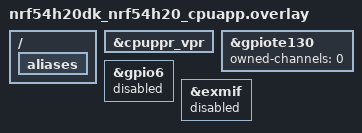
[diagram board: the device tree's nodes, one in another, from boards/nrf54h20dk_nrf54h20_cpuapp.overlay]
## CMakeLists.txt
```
#
# Copyright (c) 2024 Nordic Semiconductor ASA
#
# SPDX-License-Identifier: LicenseRef-Nordic-5-Clause
#

cmake_minimum_required(VERSION 3.20.0)

find_package(Zephyr REQUIRED HINTS $ENV{ZEPHYR_BASE})

if(NOT SYSBUILD)
	message(FATAL_ERROR
		" This is a multi-image application that should be built using sysbuild.\n"
		" Add --sysbuild argument to west build command to prepare all the images.")
endif()

project(idle_ppr)

target_sources(app PRIVATE src/main.c)
```

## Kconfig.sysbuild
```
#
# Copyright (c) 2024 Nordic Semiconductor ASA
#
# SPDX-License-Identifier: LicenseRef-Nordic-5-Clause
#

choice NETCORE
	default NETCORE_REMOTE

config NETCORE_REMOTE
	bool "Remote image"

endchoice

config NETCORE_IMAGE_NAME
	default "remote" if NETCORE_REMOTE

config NETCORE_IMAGE_PATH
	default "$(ZEPHYR_NRF_MODULE_DIR)/tests/benchmarks/multicore/idle_ppr/remote" if NETCORE_REMOTE

choice PPRCORE
	default PPRCORE_REMOTE

config PPRCORE_REMOTE
	bool "Remote image"

endchoice

config PPRCORE_IMAGE_NAME
	default "remote_ppr" if PPRCORE_REMOTE

config PPRCORE_IMAGE_PATH
	default "$(ZEPHYR_NRF_MODULE_DIR)/tests/benchmarks/multicore/idle_ppr/remote" if PPRCORE_REMOTE

source "share/sysbuild/Kconfig"
```

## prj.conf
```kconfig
CONFIG_GPIO=y

CONFIG_BOOT_BANNER=n
CONFIG_NCS_BOOT_BANNER=n
CONFIG_ASSERT=y

# Enable for debugging purposes only
CONFIG_PRINTK=n
CONFIG_LOG=n
CONFIG_CONSOLE=n
CONFIG_UART_CONSOLE=n
CONFIG_SERIAL=n
```

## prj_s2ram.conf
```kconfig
CONFIG_PM=y
CONFIG_PM_S2RAM=y
CONFIG_POWEROFF=y

CONFIG_PM_DEVICE=y
CONFIG_PM_DEVICE_RUNTIME=y

CONFIG_BOOT_BANNER=n
CONFIG_NCS_BOOT_BANNER=n
CONFIG_PRINTK=n
CONFIG_LOG=n
CONFIG_CONSOLE=n
CONFIG_UART_CONSOLE=n
CONFIG_SERIAL=n

CONFIG_ASSERT=y
CONFIG_GPIO=y
```

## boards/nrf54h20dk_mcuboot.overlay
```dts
/*
 * Copyright (c) 2025 Nordic Semiconductor ASA
 *
 * SPDX-License-Identifier: LicenseRef-Nordic-5-Clause
 */

/ {
	aliases {
		/delete-property/ led1;
	};
};

/delete-node/ &led1;

&gpiote130 {
	status = "okay";
	owned-channels = <0>;
};
```

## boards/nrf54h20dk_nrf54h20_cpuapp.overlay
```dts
/*
 * Copyright (c) 2024 Nordic Semiconductor ASA
 *
 * SPDX-License-Identifier: LicenseRef-Nordic-5-Clause
 */

&cpuppr_vpr {
	status = "okay";
};

/ {
	aliases {
		/delete-property/ led1;
	};
};

/delete-node/ &led1;

&gpiote130 {
	status = "okay";
	owned-channels = <0>;
};

&gpio6 {
	status = "disabled";
};

&exmif {
	status = "disabled";
};
```

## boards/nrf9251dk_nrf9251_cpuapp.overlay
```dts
/*
 * Copyright (c) 2026 Nordic Semiconductor ASA
 *
 * SPDX-License-Identifier: LicenseRef-Nordic-5-Clause
 */

&gpiote130 {
	status = "okay";
};

&cpuppr_vpr {
	status = "okay";
};

&uart132 {
	status = "reserved";
	interrupt-parent = <&cpuppr_clic>;
};
```

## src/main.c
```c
/*
 * Copyright (c) 2024 Nordic Semiconductor ASA
 *
 * SPDX-License-Identifier: LicenseRef-Nordic-5-Clause
 */
#include <zephyr/kernel.h>
#include <zephyr/drivers/gpio.h>

#include <zephyr/logging/log.h>
LOG_MODULE_REGISTER(idle_ppr, LOG_LEVEL_INF);

static const struct gpio_dt_spec led = GPIO_DT_SPEC_GET(DT_ALIAS(led0), gpios);

/* Variables used to make CPU active for ~1 second */
static struct k_timer my_timer;
static bool timer_expired;

void my_timer_handler(struct k_timer *dummy)
{
	timer_expired = true;
}

int main(void)
{
	int counter = 0;
	int ret;

	LOG_INF("Multicore idle_ppr test on %s", CONFIG_BOARD_TARGET);
	LOG_INF("Main sleeps for %d ms", CONFIG_TEST_SLEEP_DURATION_MS);

	ret = gpio_is_ready_dt(&led);
	if (!ret) {
		LOG_ERR("LED is not ready");
	}
	__ASSERT(ret, "LED is not ready\n");

	ret = gpio_pin_configure_dt(&led, GPIO_OUTPUT_ACTIVE);
	if (ret < 0) {
		LOG_ERR("Unable to configure GPIO as output");
	}
	__ASSERT(ret == 0, "Unable to configure GPIO as output\n");

	k_timer_init(&my_timer, my_timer_handler, NULL);

	/* Run test forever */
	while (1) {
		timer_expired = false;

		/* Turn ON LED */
		ret = gpio_pin_set_dt(&led, 1);

		/* start a one-shot timer that expires after 1 second */
		k_timer_start(&my_timer, K_MSEC(1000), K_NO_WAIT);

		if (ret < 0) {
			LOG_ERR("Unable to turn on LED");
		}
		__ASSERT(ret == 0, "Unable to turn on LED\n");

		/* Keep CPU active for ~ 1 second */
		while (!timer_expired) {
			k_busy_wait(10000);
			k_yield();
		}

		LOG_INF("Run %d", counter);
		counter++;

		/* Turn OFF LED */
		ret = gpio_pin_set_dt(&led, 0);
		if (ret < 0) {
			LOG_ERR("Unable to turn off LED");
		}
		__ASSERT(ret == 0, "Unable to turn off LED\n");

		/* Sleep / enter low power state */
		k_msleep(CONFIG_TEST_SLEEP_DURATION_MS);
	}

	return 0;
}
```
